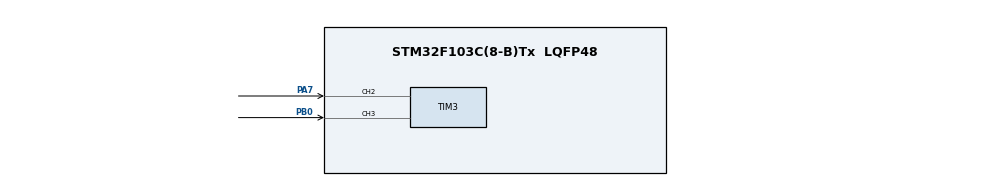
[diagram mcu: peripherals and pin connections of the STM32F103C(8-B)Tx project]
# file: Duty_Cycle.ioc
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Mcu.Family=STM32F1
Mcu.Name=STM32F103C(8-B)Tx
Mcu.Package=LQFP48
NVIC.PriorityGroup=NVIC_PRIORITYGROUP_4
NVIC.TIM3_IRQn=true\:0\:0\:false\:false\:true\:true\:true\:true
PA13.Mode=Serial_Wire
PA13.Signal=SYS_JTMS-SWDIO
PA14.Mode=Serial_Wire
PA14.Signal=SYS_JTCK-SWCLK
PA7.Signal=S_TIM3_CH2
PB0.Signal=S_TIM3_CH3
PD0-OSC_IN.Mode=HSE-External-Oscillator
PD0-OSC_IN.Signal=RCC_OSC_IN
PD1-OSC_OUT.Mode=HSE-External-Oscillator
PD1-OSC_OUT.Signal=RCC_OSC_OUT
ProjectManager.HeapSize=0x200
ProjectManager.StackSize=0x400
ProjectManager.TargetToolchain=MDK-ARM V5.32
RCC.APB1Freq_Value=8000000
RCC.APB2Freq_Value=8000000
SH.S_TIM3_CH2.0=TIM3_CH2,Input_Capture2_from_TI2
SH.S_TIM3_CH2.1=TIM3_CH2,TriggerSource_TI2FP2
SH.S_TIM3_CH3.0=TIM3_CH3,Input_Capture3_from_TI3
TIM3.Channel-Input_Capture2_from_TI2=TIM_CHANNEL_2
TIM3.Channel-Input_Capture3_from_TI3=TIM_CHANNEL_3
TIM3.ICPolarity_CH3=TIM_INPUTCHANNELPOLARITY_FALLING
VP_TIM3_VS_ClockSourceINT.Mode=Internal
VP_TIM3_VS_ControllerModeReset.Mode=Reset Mode
board=custom

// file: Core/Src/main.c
/* USER CODE BEGIN Header */
/**
  ******************************************************************************
  * @file           : main.c
  * @brief          : Main program body
  ******************************************************************************
  * @attention
  *
  * Copyright (c) 2022 STMicroelectronics.
  * All rights reserved.
  *
  * This software is licensed under terms that can be found in the LICENSE file
  * in the root directory of this software component.
  * If no LICENSE file comes with this software, it is provided AS-IS.
  *
  ******************************************************************************
  */
/* USER CODE END Header */
#include "main.h"
#include "tim.h"
#include "gpio.h"

void SystemClock_Config(void);
/* USER CODE BEGIN PFP */
uint32_t IC_val1 = 0;
uint32_t IC_val2 = 0;
uint32_t freq;
uint32_t duty;

void HAL_TIM_IC_CaptureCallback(TIM_HandleTypeDef *htim)
{
	if(htim -> Channel == HAL_TIM_ACTIVE_CHANNEL_2){
		IC_val1 = HAL_TIM_ReadCapturedValue(htim, TIM_CHANNEL_3);
		if(IC_val1 != 0)
		{
			IC_val2 = HAL_TIM_ReadCapturedValue(htim, TIM_CHANNEL_3);
			duty = IC_val2/IC_val1;
			freq = (2*HAL_RCC_GetPCLK1Freq()/IC_val1);
		}
		else
		{
			duty = 0;
			freq = 0;
		}
	}
}
/* USER CODE END PFP */

int main(void)
{

  /* MCU Configuration--------------------------------------------------------*/

  /* Reset of all peripherals, Initializes the Flash interface and the Systick. */
  HAL_Init();

  /* Configure the system clock */
  SystemClock_Config();

  /* Initialize all configured peripherals */
  MX_GPIO_Init();
  MX_TIM3_Init();
  /* USER CODE BEGIN 2 */
	HAL_TIM_IC_Start_IT(&htim3, TIM_CHANNEL_2);
	HAL_TIM_IC_Start_IT(&htim3, TIM_CHANNEL_3);
  /* USER CODE END 2 */

  /* Infinite loop */
  while (1)
  {

  }
}

void SystemClock_Config(void)
{
  RCC_OscInitTypeDef RCC_OscInitStruct = {0};
  RCC_ClkInitTypeDef RCC_ClkInitStruct = {0};

  /** Initializes the RCC Oscillators according to the specified parameters
  * in the RCC_OscInitTypeDef structure.
  */
  RCC_OscInitStruct.OscillatorType = RCC_OSCILLATORTYPE_HSI;
  RCC_OscInitStruct.HSIState = RCC_HSI_ON;
  RCC_OscInitStruct.HSICalibrationValue = RCC_HSICALIBRATION_DEFAULT;
  RCC_OscInitStruct.PLL.PLLState = RCC_PLL_NONE;
  if (HAL_RCC_OscConfig(&RCC_OscInitStruct) != HAL_OK)
  {
    Error_Handler();
  }

  /** Initializes the CPU, AHB and APB buses clocks
  */
  RCC_ClkInitStruct.ClockType = RCC_CLOCKTYPE_HCLK|RCC_CLOCKTYPE_SYSCLK
                              |RCC_CLOCKTYPE_PCLK1|RCC_CLOCKTYPE_PCLK2;
  RCC_ClkInitStruct.SYSCLKSource = RCC_SYSCLKSOURCE_HSI;
  RCC_ClkInitStruct.AHBCLKDivider = RCC_SYSCLK_DIV1;
  RCC_ClkInitStruct.APB1CLKDivider = RCC_HCLK_DIV1;
  RCC_ClkInitStruct.APB2CLKDivider = RCC_HCLK_DIV1;

  if (HAL_RCC_ClockConfig(&RCC_ClkInitStruct, FLASH_LATENCY_0) != HAL_OK)
  {
    Error_Handler();
  }
}

void Error_Handler(void)
{
  __disable_irq();
  while (1)
  {
  }
}
